# SIMCOP register map
Vendor: Texas Instruments
Peripheral module from a debugger description file (folder TDA2Px).
Registers are 32-bit, access per field, reset 0x0 unless marked. A register's access mark holds for its fields unless they carry their own. Offsets are as the file gives them; lines under a group give offsets from that group; [hi:lo] are bit positions; {n}, {i} and the like mark numbered series; 'fields as' and 'values as' point back to an identical list; <NAME> marks a mode.

## SIMCOP
0x00 SIMCOP_HL_REVISION ro reset not defined — IP Revision Identifier (X.Y.R) Used by software to track features, bugs, and compatibility
  [31:0] REVISION — IP Revision
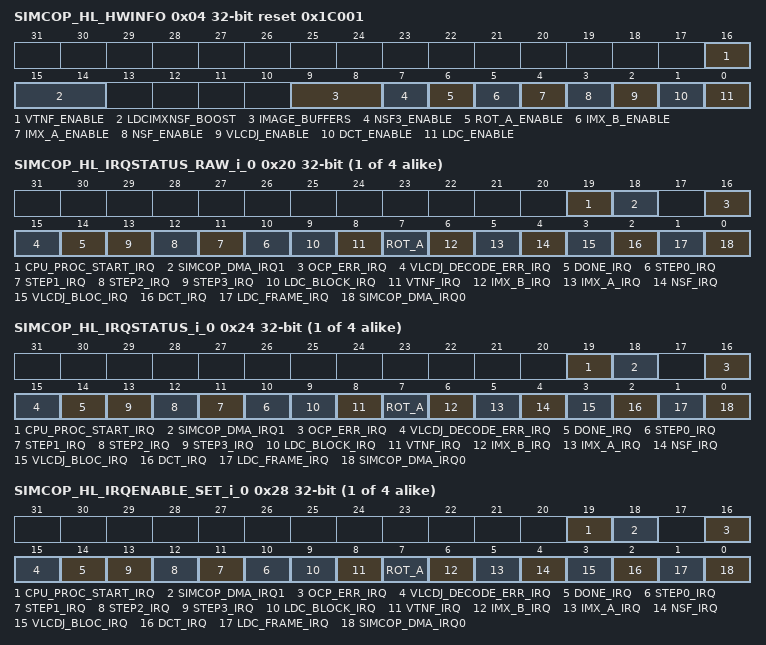
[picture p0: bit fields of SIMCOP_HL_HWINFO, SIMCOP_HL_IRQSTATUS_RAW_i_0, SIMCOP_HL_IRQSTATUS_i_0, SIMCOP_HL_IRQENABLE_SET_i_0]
0x04 SIMCOP_HL_HWINFO ro reset 0x1C001 — Information about the IP module's hardware configuration. It provides information about the RTL generic parameters.
  [16] VTNF_ENABLE — The VTNF module is present when this parameter is set.
  [15:14] LDCIMXNSF_BOOST
    0=ZERO (SIMCOP receives a 200 MHz clock driving all sub-modules); 1=ONE (SIMCOP receives a 400 MHz clock. Some modules receive the 400 Mhz clock and others receive 400/2=200 Mhz.); 3=THREE (SIMCOP receives only one main clock for all the modules.); 2=TWO (SIMCOP receives a main clock @ 304 Mhz plus a clock @ 426 Mhz for LDC, NSF and iMX.)
  [9:8] IMAGE_BUFFERS — This parameter defines the image buffer count.
    0=IM4 (4 Image buffers (#e, #f, #g, #h)); 1=IM8 (8 Image buffers)
  [7] NSF3_ENABLE — The NSF3 module is present when this parameter is set.
    0=DISABLE (Disabled at design time); 1=ENABLE (Enabled at design time)
  [6] ROT_A_ENABLE — The ROT #a module is present when this parameter is set.
    values as NSF3_ENABLE
  [5] IMX_B_ENABLE — The iMX #b module and the CMD#b, COEFF#b memories are present when this parameter is set.
    values as NSF3_ENABLE
  [4] IMX_A_ENABLE — The iMX #a module and the CMD#a, COEFF#a memories are present when this parameter is set.
    values as NSF3_ENABLE
  [3] NSF_ENABLE — The NSF2 module is present when this parameter is set.
    values as NSF3_ENABLE
  [2] VLCDJ_ENABLE — The VLCD module and the QUANT, HUFFMAN, BITSTREAM memories are present when this parameter is set.
    values as NSF3_ENABLE
  [1] DCT_ENABLE — The DCT module is present when this parameter is set.
    values as NSF3_ENABLE
  [0] LDC_ENABLE — The LDC module and the LDC LUT are present when this parameter is set.
    values as NSF3_ENABLE
0x10 SIMCOP_HL_SYSCONFIG — This register controls the various parameters of the OCP interface
  [0] SOFTRESET rw — Software reset
    0=DONE (Reset done, no pending action); 1=PENDING (Reset (software or other) ongoing)
0x1C SIMCOP_HL_IRQ_EOI — End Of Interrupt number specification
  [1:0] LINE_NUMBER rw — Software End Of Interrupt (EOI) control. Write number of interrupt output.
    0=READ0 (Reads always 0 (no EOI memory)); 1=EOI1 (EOI for interrupt output line #1); 3=EOI3 (EOI for interrupt output line #3); 2=EOI2 (EOI for interrupt output line #2)
{0x20+0x10*i} SIMCOP_HL_IRQSTATUS_RAW_i_{i} (i=0..3) — Per-event raw interrupt status vector Raw status is set even if event is not enabled. Write 1 to set the (raw) status, mostly for debug.
  [19] CPU_PROC_START_IRQ rw — Event triggered by the HW sequencer to instruct the CPU to process a macro block
    0=NOACTION; 1=SET (Set event (debug))
  [18] SIMCOP_DMA_IRQ1 ro — Event triggered by the SIMCOP DMA. This event is automatically cleared at SIMCOP level when it is cleared at SIMCOP DMA level Check SIMCOP DMA IRQ registers.
    0=NOEVENT (No event pending); 1=PENDING (Event pending)
  [16] OCP_ERR_IRQ rw — An OCP error has been received on the OCPMB master port.
    0=NOACTION; 1=SET (Set event (debug))
  [15] VLCDJ_DECODE_ERR_IRQ ro — This bit field is reserved and users should write the reset value to this bit location. A decode error has been signaled by the VLCDJ module
  [14] DONE_IRQ rw — Event triggered when the HW sequencer finishes the sequence: - the sequence step counter has reached the limit - all accelerator and DMA events for the last sequence step have been received.
    0=NOACTION; 1=SET (Set event (debug))
  [n+10] STEP{n}_IRQ rw (n=0..3) — Event triggered when STEP{n} is activated by the HW sequencer
    0=NOACTION; 1=SET (Set event (debug))
  [9] LDC_BLOCK_IRQ rw — This event is triggered by LDC when a macro-block has been processed
    0=NOACTION; 1=SET (Set event (debug))
  [8] VTNF_IRQ rw — Event triggered by the VTNF imaging accelerator when processing of a block is done.
    0=NOACTION; 1=SET (Set event (debug))
  [7] ROT_A ro — This bit field is reserved and users should write the reset value to this bit location. Event triggered by the ROT #a engine
  [6] IMX_B_IRQ ro — This bit field is reserved and users should write the reset value to this bit location. Event triggered when iMX has executed a SLEEP instruction.
  [5] IMX_A_IRQ ro — This bit field is reserved and users should write the reset value to this bit location. Event triggered when iMX has executed a SLEEP instruction.
  [4] NSF_IRQ ro — This bit field is reserved and users should write the reset value to this bit location. Event triggered by the NSF2 imaging accelerator when processing of a block is done.
  [3] VLCDJ_BLOC_IRQ ro — This bit field is reserved and users should write the reset value to this bit location. This event is triggered by VLCDJ when a macro-bloc has been processed (encode/decode)
  [2] DCT_IRQ ro — This bit field is reserved and users should write the reset value to this bit location.Event triggered when a block has been processed by the DCT module and the filter outcome has been stored to an image buffer.
  [1] LDC_FRAME_IRQ rw — This event is triggered by LDC when a full frame has been processed
    0=NOACTION; 1=SET (Set event (debug))
  [0] SIMCOP_DMA_IRQ0 ro — Event triggered by the SIMCOP DMA. This event is automatically cleared at SIMCOP level when it is cleared at SIMCOP DMA level Check SIMCOP DMA IRQ registers.
    0=NOEVENT (No event pending); 1=PENDING (Event pending)
{0x24+0x10*i} SIMCOP_HL_IRQSTATUS_i_{i} (i=0..3) — Per-event 'enabled' interrupt status vector Enabled status isn't set unless event is enabled. Write 1 to clear the status after interrupt has been serviced (raw status gets cleared, i.e. even if not enabled). When AND mode is selected (.IRQx_MODE=1, x is the IRQ line number), the SIMCOP_HL_IRQSTATUS__x register equals 0 until all enabled events have occured. Intermediate state can be read from SIMCOP_HL_IRQSTATUS_RAW__x
  [19] CPU_PROC_START_IRQ rw — Event triggered by the HW sequencer to instruct the CPU to process a macro block
    0=NOACTION; 1=CLEAR (Clear (raw) event)
  [18] SIMCOP_DMA_IRQ1 ro — Event triggered by the SIMCOP DMA. This event is automatically cleared at SIMCOP level when it is cleared at SIMCOP DMA level Check SIMCOP DMA IRQ registers.
    0=NOEVENT (No (enabled) event pending); 1=PENDING (Event pending)
  [16] OCP_ERR_IRQ rw — An OCP error has been received on the OCPMB master port.
    0=NOACTION; 1=CLEAR (Clear (raw) event)
  [15] VLCDJ_DECODE_ERR_IRQ ro — This bit field is reserved and users should write the reset value to this bit location. A decode error has been signaled by the VLCDJ module
  [14] DONE_IRQ rw — Event triggered when the HW sequencer finishes the sequence: - the sequence step counter has reached the limit - all accelerator and DMA events for the last sequence step have been received.
    0=NOACTION; 1=CLEAR (Clear (raw) event)
  [n+10] STEP{n}_IRQ rw (n=0..3) — Event triggered when STEP{n} is activated by the HW sequencer
    0=NOACTION; 1=CLEAR (Clear (raw) event)
  [9] LDC_BLOCK_IRQ rw — This event is triggered by LDC when a macro-block has been processed
    0=NOACTION; 1=CLEAR (Clear (raw) event)
  [8] VTNF_IRQ rw — Event triggered by the VTNF imaging accelerator when processing of a block is done.
    0=NOACTION; 1=CLEAR (Clear (raw) event)
  [7] ROT_A ro — This bit field is reserved and users should write the reset value to this bit location. Event triggered by the ROT #a engine
  [6] IMX_B_IRQ ro — This bit field is reserved and users should write the reset value to this bit location. Event triggered when iMX has executed a SLEEP instruction.
  [5] IMX_A_IRQ ro — This bit field is reserved and users should write the reset value to this bit location. Event triggered when iMX has executed a SLEEP instruction.
  [4] NSF_IRQ ro — This bit field is reserved and users should write the reset value to this bit location. Event triggered by the NSF2 imaging accelerator when processing of a block is done.
  [3] VLCDJ_BLOC_IRQ ro — This bit field is reserved and users should write the reset value to this bit location. This event is triggered by VLCDJ when a macro-bloc has been processed (encode/decode)
  [2] DCT_IRQ ro — This bit field is reserved and users should write the reset value to this bit location. Event triggered when a block has been processed by the DCT module and the filter outcome has been stored to an image buffer.
  [1] LDC_FRAME_IRQ rw — This event is triggered by LDC when a full frame has been processed
    0=NOACTION; 1=CLEAR (Clear (raw) event)
  [0] SIMCOP_DMA_IRQ0 ro — Event triggered by the SIMCOP DMA. This event is automatically cleared at SIMCOP level when it is cleared at SIMCOP DMA level Check SIMCOP DMA IRQ registers.
    values as SIMCOP_DMA_IRQ1
{0x28+0x10*i} SIMCOP_HL_IRQENABLE_SET_i_{i} (i=0..3) — Per-event interrupt enable bit vector Write 1 to set (enable interrupt). Readout equal to corresponding _CLR register.
  [19] CPU_PROC_START_IRQ rw — Event triggered by the HW sequencer to instruct the CPU to process a macro block
    0=NOACTION; 1=ENABLE (Enable interrupt)
  [18] SIMCOP_DMA_IRQ1 rw — Event triggered by the SIMCOP DMA. Check SIMCOP DMA IRQ registers.
    0=NOACTION; 1=ENABLE (Enable interrupt)
  [16] OCP_ERR_IRQ rw — An OCP error has been received on the OCPMB master port.
    0=NOACTION; 1=ENABLE (Enable interrupt)
  [15] VLCDJ_DECODE_ERR_IRQ ro — This bit field is reserved and users should write the reset value to this bit location. A decode error has been signaled by the VLCDJ module
  [14] DONE_IRQ rw — Event triggered when the HW sequencer finishes the sequence: - the sequence step counter has reached the limit - all accelerator and DMA events for the last sequence step have been received.
    0=NOACTION; 1=ENABLE (Enable interrupt)
  [n+10] STEP{n}_IRQ rw (n=0..3) — Event triggered when STEP{n} is activated by the HW sequencer
    0=NOACTION; 1=ENABLE (Enable interrupt)
  [9] LDC_BLOCK_IRQ rw — This event is triggered by LDC when a macro-block has been processed
    0=NOACTION; 1=ENABLE (Enable interrupt)
  [8] VTNF_IRQ rw — Event triggered by the VTNF imaging accelerator when processing of a block is done.
    0=NOACTION; 1=ENABLE (Enable interrupt)
  [7] ROT_A ro — This bit field is reserved and users should write the reset value to this bit location. Event triggered by the ROT #a engine
  [6] IMX_B_IRQ ro — This bit field is reserved and users should write the reset value to this bit location. Event triggered when iMX has executed a SLEEP instruction.
  [5] IMX_A_IRQ ro — This bit field is reserved and users should write the reset value to this bit location. Event triggered when iMX has executed a SLEEP instruction.
  [4] NSF_IRQ ro — This bit field is reserved and users should write the reset value to this bit location. Event triggered by the NSF2 imaging accelerator when processing of a block is done.
  [3] VLCDJ_BLOC_IRQ ro — This bit field is reserved and users should write the reset value to this bit location. This event is triggered by VLCDJ when a macro-bloc has been processed (encode/decode)
  [2] DCT_IRQ ro — This bit field is reserved and users should write the reset value to this bit location. Event triggered when a block has been processed by the DCT module and the filter outcome has been stored to an image buffer.
  [1] LDC_FRAME_IRQ rw — This event is triggered by LDC when a full frame has been processed
    0=NOACTION; 1=ENABLE (Enable interrupt)
  [0] SIMCOP_DMA_IRQ0 rw — Event triggered by the SIMCOP DMA. Check SIMCOP DMA IRQ registers.
    0=NOACTION; 1=ENABLE (Enable interrupt)
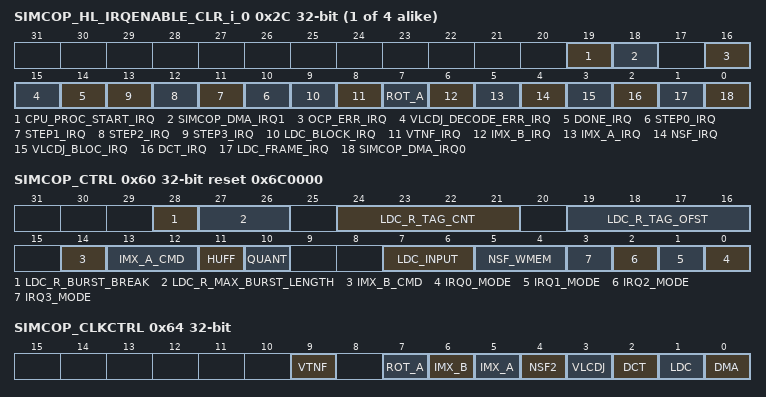
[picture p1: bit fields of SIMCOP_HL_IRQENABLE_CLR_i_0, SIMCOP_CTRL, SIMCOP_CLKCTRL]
{0x2C+0x10*i} SIMCOP_HL_IRQENABLE_CLR_i_{i} (i=0..3) — Per-event interrupt enable bit vector Write 1 to clear (disable interrupt). Readout equal to corresponding _SET register.
  [19] CPU_PROC_START_IRQ rw — Event triggered by the HW sequencer to instruct the CPU to process a macro block
    0=NOACTION; 1=DISABLE (Disable interrupt)
  [18] SIMCOP_DMA_IRQ1 rw — Event triggered by the SIMCOP DMA. Check SIMCOP DMA IRQ registers.
    0=NOACTION; 1=DISABLE (Disable interrupt)
  [16] OCP_ERR_IRQ rw — An OCP error has been received on the OCPMB master port.
    0=NOACTION; 1=DISABLE (Disable interrupt)
  [15] VLCDJ_DECODE_ERR_IRQ ro — This bit field is reserved and users should write the reset value to this bit location. A decode error has been signaled by the VLCDJ module
  [14] DONE_IRQ rw — Event triggered when the HW sequencer finishes the sequence: - the sequence step counter has reached the limit - all accelerator and DMA events for the last sequence step have been received.
    0=NOACTION; 1=DISABLE (Disable interrupt)
  [n+10] STEP{n}_IRQ rw (n=0..3) — Event triggered when STEP{n} is activated by the HW sequencer
    0=NOACTION; 1=DISABLE (Disable interrupt)
  [9] LDC_BLOCK_IRQ rw — This event is triggered by LDC when a macro-block has been processed
    0=NOACTION; 1=DISABLE (Disable interrupt)
  [8] VTNF_IRQ rw — Event triggered by the VTNF imaging accelerator when processing of a block is done.
    0=NOACTION; 1=DISABLE (Disable interrupt)
  [7] ROT_A ro — This bit field is reserved and users should write the reset value to this bit location. Event triggered by the ROT #a engine
  [6] IMX_B_IRQ ro — This bit field is reserved and users should write the reset value to this bit location. Event triggered when iMX has executed a SLEEP instruction.
  [5] IMX_A_IRQ ro — This bit field is reserved and users should write the reset value to this bit location. Event triggered when iMX has executed a SLEEP instruction.
  [4] NSF_IRQ ro — This bit field is reserved and users should write the reset value to this bit location. Event triggered by the NSF2 imaging accelerator when processing of a block is done.
  [3] VLCDJ_BLOC_IRQ ro — This bit field is reserved and users should write the reset value to this bit location. This event is triggered by VLCDJ when a macro-bloc has been processed (encode/decode)
  [2] DCT_IRQ ro — This bit field is reserved and users should write the reset value to this bit location. Event triggered when a block has been processed by the DCT module and the filter outcome has been stored to an image buffer.
  [1] LDC_FRAME_IRQ rw — This event is triggered by LDC when a full frame has been processed
    0=NOACTION; 1=DISABLE (Disable interrupt)
  [0] SIMCOP_DMA_IRQ0 rw — Event triggered by the SIMCOP DMA. Check SIMCOP DMA IRQ registers.
    0=NOACTION; 1=DISABLE (Disable interrupt)
0x60 SIMCOP_CTRL reset 0x6C0000 — SIMCOP control register
  [28] LDC_R_BURST_BREAK rw — Controls if bursts issued by LDC bridge could cross burst length boundaries. When this register is set, the LDC module only issues OCP aligned bursts. Register can only be used when LDC_R_MAX_BURST_LENGTH is 32, 64 or 128 bytes.
    0=YES; 1=NO (No. OCP transactions must be splitted)
  [27:26] LDC_R_MAX_BURST_LENGTH rw — Limits the maximum burst length that could be used by LDC
    0=B128 (8x128); 1=B96 (6x128); 3=B32 (2x128); 2=B64 (4x128)
  [24:21] LDC_R_TAG_CNT rw — Limits the maximum number of outstanding LDC requests to LDC_R_TAG_CNT+1
  [19:16] LDC_R_TAG_OFST rw — Reserved. Values written to this register are ignored. (register required for legacy SW)
  [14] IMX_B_CMD rw — This bit field is reserved and users should write the reset value to this bit location. Switch for iMX # command memory
    0=COPR (Coprocessor bus); 1=IMXB (IMX #B instruction read / write)
  [13:12] IMX_A_CMD rw — This bit field is reserved and users should write the reset value to this bit location. Switch for iMX #a command memory
    0=COPR (Coprocessor bus); 1=IMXA (IMX #A instruction read / write); 2=IMXB (IMX #B instruction read / write)
  [11] HUFF rw — This bit field is reserved and users should write the reset value to this bit location. Switch for huffman table
    0=COPR (Coprocessor); 1=VLCDJ (VLCDJ huffman table read)
  [10] QUANT rw — This bit field is reserved and users should write the reset value to this bit location. Switch for quantization table
    0=COPR (Coprocessor bus); 1=VLCDJ (VLCDJ quantization table read)
  [7:6] LDC_INPUT rw — This bit field is reserved and users should write the reset value to this bit location. Selects input data buffer for LDC. Memories attached to LDC as working memories can't be used by any other accelerators. HWSEQ or HWSEQ SW override settings are ignored for those memories.
    0=NONE (No input memory attached); 1=IMBUF2 (reserved); 3=LDC_PRIVATE (Use LDC private input memory.); 2=IMBUF4 (use image buffers #a #b #c #d)
  [5:4] NSF_WMEM rw — This bit field is reserved and users should write the reset value to this bit location. Selects working memory for NSF. Memories attached to NSF as working memories can't be used by any other accelerators. HWSEQ or HWSEQ SW override settings are ignored for those memories.
    0=NONE (No working memory attached to NSF2. NSF2 can't be used.); 1=COEFF_A (iMX #a coefficient memory used.); 3=IMBUFF_4 (Image buffers #a, #b, #c, #d used. Those image buffers can't be used for other purposes. This setting has higher priority than the context configuration); 2=IMBUFF_2 (Image buffers #a #b used. Those image buffers can't be used for other purposes. This setting has higher priority than the context configuration)
  [n] IRQ{n}_MODE rw (n=0..3) — Interrupt generation method
    0=OR (The interrupt line is asserted when one of the events enabled in SIMCOP_HL_IRQENABLE_SET__{n} / SIMCOP_HL_IRQENABLE_CLR__{n} is pending); 1=AND (The interrupt line is asserted when all events enabled in SIMCOP_HL_IRQENABLE_SET__{n} / SIMCOP_HL_IRQENABLE_CLR__{n} are pending)
0x64 SIMCOP_CLKCTRL — SIMCOP clock control register. Use to enable/disable the interface and functional clock of SIMCOP sub-modules. Disabled modules can't be accessed: read/writes return SResp=ERR
  [all] fields
    0=WOFF (Request shutdown of the sub-module. No effect if the sub-module clock is already off.); 1=WON (Request enable of the sub-module. No effect if the sub-module clock is already on.)
  [9] VTNF rw
  [7] ROT_A rw — This bit field is reserved and users should write the reset value to this bit location. ROT A
  [6] IMX_B rw — This bit field is reserved and users should write the reset value to this bit location. IMX B
  [5] IMX_A rw — This bit field is reserved and users should write the reset value to this bit location. IMX A
  [4] NSF2 rw — This bit field is reserved and users should write the reset value to this bit location. NSF2
  [3] VLCDJ rw — This bit field is reserved and users should write the reset value to this bit location. VLCDJ
  [2] DCT rw — This bit field is reserved and users should write the reset value to this bit location. DCT
  [1] LDC rw
  [0] DMA rw
0xFC SIMCOP_CTRL2 — Simcop control register
  [11:0] LDCR_BW_CTRL rw — Limits the mean bandwidth (computed over one block) that the LDC module can request for read from system memory 0: The BW limiter is bypassed 1~4095: maximum number of bytes per cycle multiplied by 2^8. Examples: 1 : 1.6 MBytes/s @ 426 MHz 4095 : 6.8 GBytes/s @ 426 Mhz
